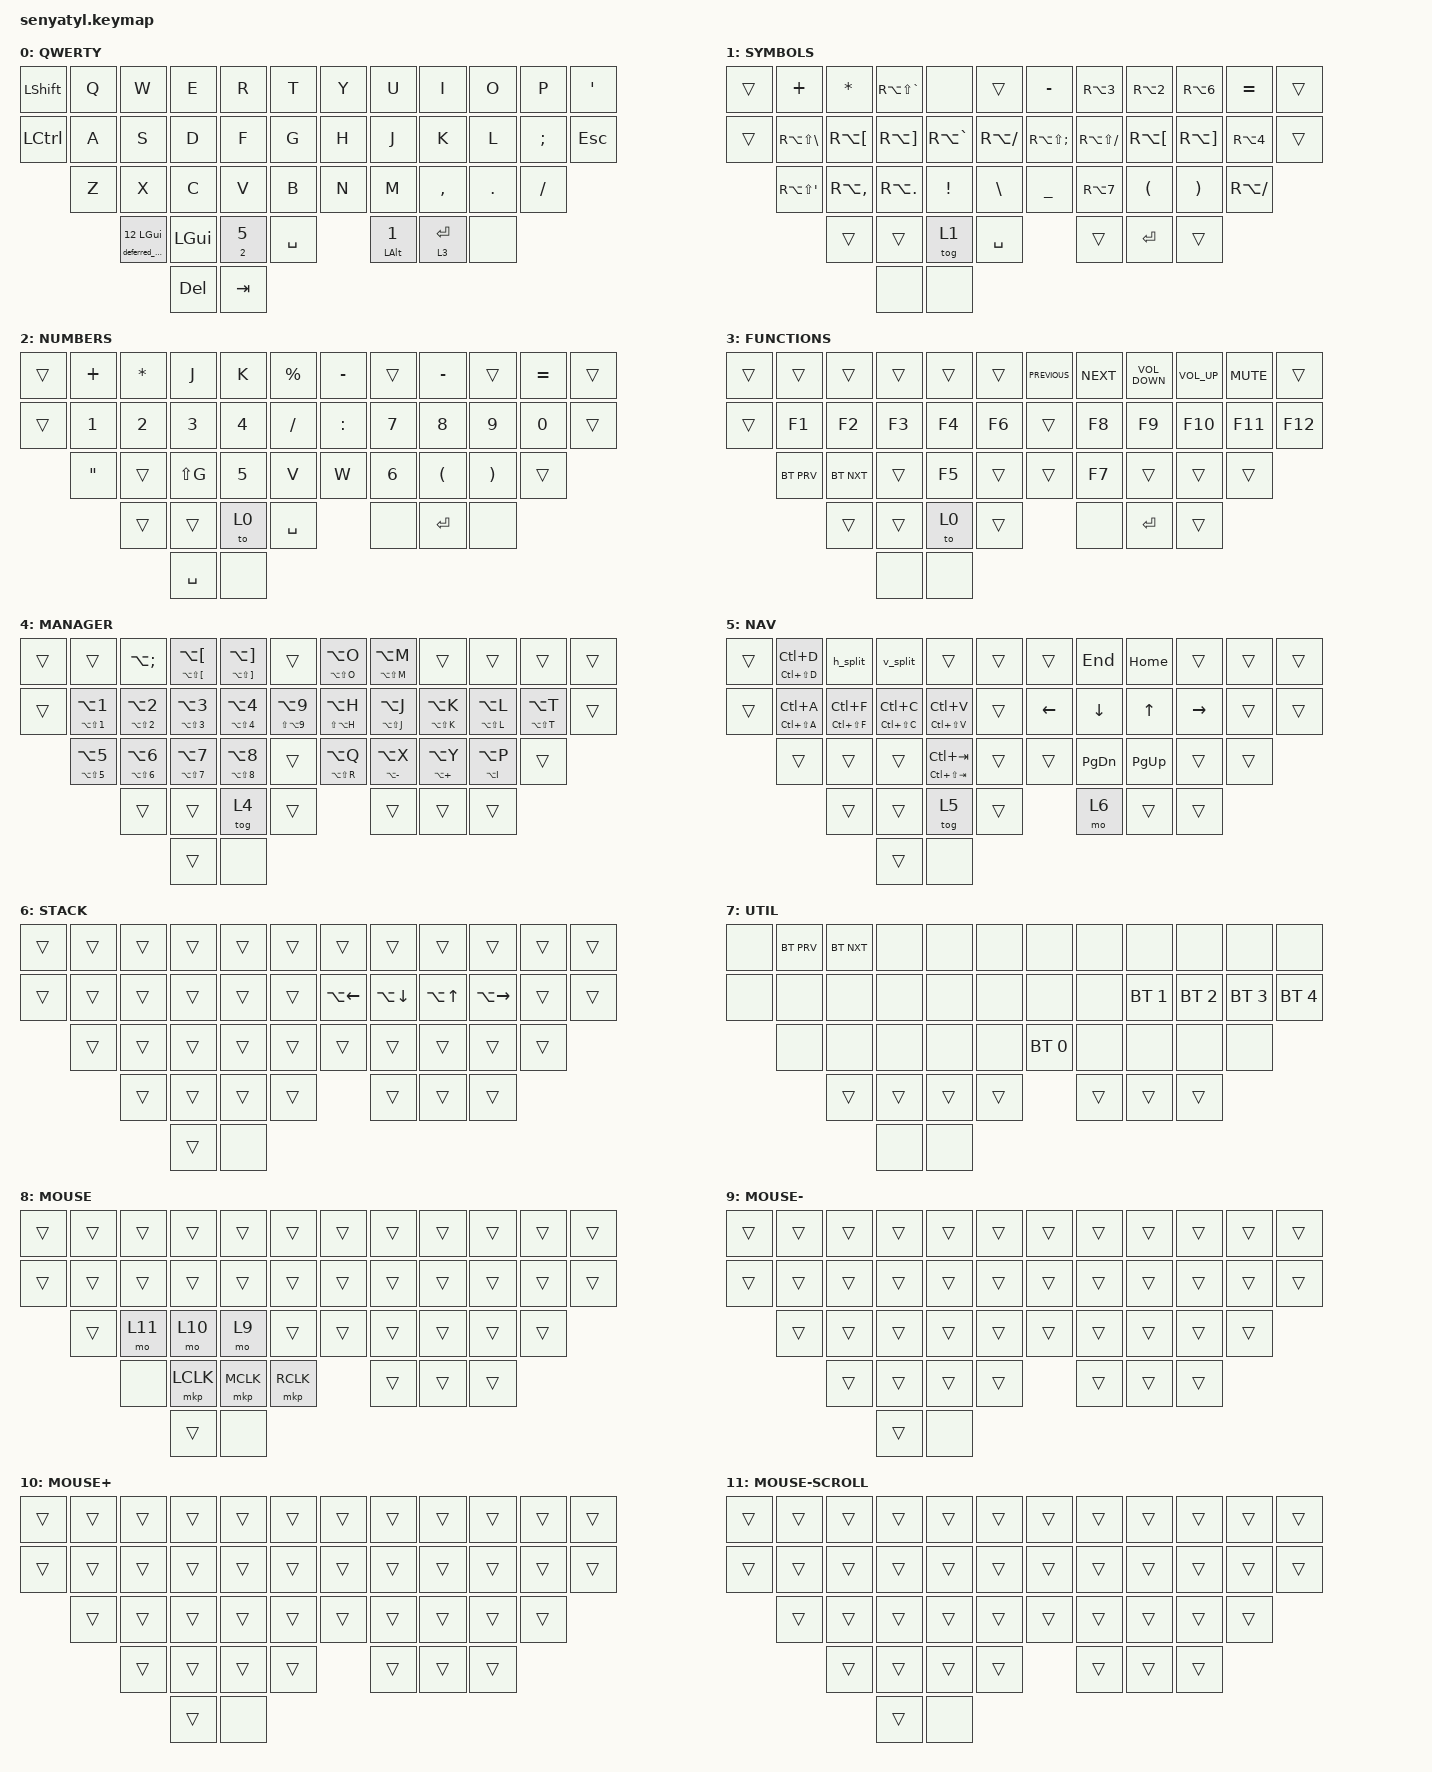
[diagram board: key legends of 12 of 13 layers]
#include <dt-bindings/zmk/mouse.h>
#include <input/processors.dtsi>
#include <zephyr/dt-bindings/input/input-event-codes.h>
#include <behaviors/deferred_mod.dtsi>
#include <behaviors/num_word.dtsi>
#include <behaviors.dtsi>
#include <dt-bindings/zmk/bt.h>
#include <dt-bindings/zmk/keys.h>
#include <dt-bindings/zmk/pointing.h>

/ {
    tapping-term-ms = <200>;
    flavor = "balanced";
    quick-tap-ms = <150>;
};

&mmv_input_listener { input-processors = <&zip_xy_scaler 2 1>; };

&msc_input_listener { input-processors = <&zip_scroll_scaler 2 1>; };

&msc {
    acceleration-exponent = <1>;
    time-to-max-speed-ms = <100>;
    delay-ms = <0>;
};

&mmv {
    time-to-max-speed-ms = <500>;
    acceleration-exponent = <1>;
    trigger-period-ms = <16>;
};

&soft_off { hold-time-ms = <2000>; };

/ {
    behaviors {
        smart_num_nav: smart_num_nav {
            compatible = "zmk,behavior-hold-tap";
            #binding-cells = <2>;
            flavor = "hold-preferred";
            tapping-term-ms = <200>;
            quick-tap-ms = <175>;
            require-prior-idle-ms = <125>;
            bindings = <&num_word_backspace>, <&nav_word>;

            display-name = "Smart Num/Nav";
        };

        nav_word: nav_word {
            compatible = "zmk,behavior-auto-layer";
            #binding-cells = <1>;
            continue-list = <LEFT DOWN UP RIGHT PG_DN PG_UP HOME END>;
            ignore-modifiers;
        };

        num_word_backspace: num_word_backspace {
            compatible = "zmk,behavior-auto-layer";
            #binding-cells = <1>;
            continue-list = <
                N1 N2 N3 N4 N5 N6 N7 N8 N9 N0
                NUMBER_1 NUMBER_2 NUMBER_3 NUMBER_4 NUMBER_5
                NUMBER_6 NUMBER_7 NUMBER_8 NUMBER_9 NUMBER_0
                PLUS MINUS ASTERISK SLASH PRCNT EQUAL COLON
                LPAR RPAR LEFT_PARENTHESIS RIGHT_PARENTHESIS
                DQT BACKSPACE BSPC
            >;

            ignore-modifiers;
        };

        sym_word: sym_word {
            compatible = "zmk,behavior-auto-layer";
            #binding-cells = <1>;
            continue-list = <
                EXCL AT HASH DLLR PRCNT CARET AMPS ASTRK LPAR RPAR
                PLUS MINUS EQUAL UNDER
                LESS_THAN GREATER_THAN SEMICOLON COLON SLASH QMARK SQT DQT
                LEFT_BRACKET RIGHT_BRACKET LEFT_BRACE RIGHT_BRACE
                BACKSLASH PIPE GRAVE TILDE BACKSPACE BSPC
                N1 N2 N3 N4 N5 N6 N7 N8 N9 N0
                LBKT RBKT BSLH SEMI COMMA PERIOD FSLH
            >;

            ignore-modifiers;
        };

        win_word: win_word {
            compatible = "zmk,behavior-auto-layer";
            #binding-cells = <1>;
            continue-list = <
                SEMICOLON LEFT_BRACKET RIGHT_BRACKET
                O M
                N1 N2 N3 N4 N5 N6 N7 N8 N9
                H J K L T
                Q P I
                X Y
                MINUS PLUS BACKSPACE BSPC
            >;

            ignore-modifiers;
        };

        del_behavior: del_behavior {
            compatible = "zmk,behavior-mod-morph";
            label = "DEL_BEHAVIOR";
            bindings = <&kp BACKSPACE>, <&kp DELETE>;

            #binding-cells = <0>;
            mods = <(MOD_LALT)>;
        };

        dot_overwrite: dot_overwrite {
            compatible = "zmk,behavior-mod-morph";
            label = "DOT_OVERWRITE";
            bindings = <&kp PERIOD>, <&kp COMMA>;

            #binding-cells = <0>;
            mods = <(MOD_LSFT)>;
        };

        smart_sym_alt: smart_sym_alt {
            compatible = "zmk,behavior-hold-tap";
            #binding-cells = <2>;
            flavor = "hold-preferred";
            tapping-term-ms = <200>;
            quick-tap-ms = <175>;
            require-prior-idle-ms = <125>;
            bindings = <&kp &sym_word>;
            display-name = "Smart Sym/Alt";
        };
    };

    combos {
        compatible = "zmk,combos";

        softoff {
            bindings = <&soft_off>;
            key-positions = <1 14 25>;
        };

        caps_word_combo {
            bindings = <&caps_word>;
            key-positions = <36 38>;
            layers = <0>;
        };

        lpkt {
            bindings = <&kp LEFT_PARENTHESIS>;
            key-positions = <4 5>;
            layers = <0>;
        };

        lbrt {
            bindings = <&kp LEFT_BRACKET>;
            key-positions = <17 16>;
            layers = <0>;
        };

        lbrs {
            bindings = <&kp LEFT_BRACE>;
            key-positions = <28 27>;
            layers = <0>;
        };

        rpkt {
            bindings = <&kp RIGHT_PARENTHESIS>;
            key-positions = <6 7>;
            layers = <0>;
        };

        rbrt {
            bindings = <&kp RIGHT_BRACKET>;
            key-positions = <19 18>;
            layers = <0>;
        };

        rbrs {
            bindings = <&kp RIGHT_BRACE>;
            key-positions = <30 30 29>;
            layers = <0>;
        };

        qw_esc {
            bindings = <&kp ESC>;
            key-positions = <25 26>;
            layers = <0>;
        };

        to_util_left {
            bindings = <&tog 7>;
            key-positions = <0 5 36>;
            layers = <0>;
        };

        to_util_right {
            bindings = <&tog 7>;
            key-positions = <6 11 38>;
            layers = <0>;
        };

        from_util_left {
            bindings = <&tog 7>;
            key-positions = <0 5 36>;
            layers = <7>;
        };

        from_util_right {
            bindings = <&tog 7>;
            key-positions = <6 11 38>;
            layers = <7>;
        };

        shrug_combo {
            bindings = <&shrug>;
            key-positions = <2 3 4>;
            layers = <1>;
        };

        sys_reset_left {
            bindings = <&sys_reset>;
            key-positions = <0 12>;
            layers = <7>;
        };

        bootloader_left {
            bindings = <&bootloader>;
            key-positions = <12 24>;
            layers = <7>;
        };

        sys_reset_right {
            bindings = <&sys_reset>;
            key-positions = <11 23>;
            layers = <7>;
        };

        bootloader_right {
            bindings = <&bootloader>;
            key-positions = <23 33>;
            layers = <7>;
        };

        bt_clear {
            bindings = <&bt BT_CLR_ALL>;
            key-positions = <4 3 2>;
            layers = <7>;
        };

        bt_clear_curr {
            bindings = <&bt BT_CLR>;
            key-positions = <14 15 16>;
            layers = <7>;
        };

        new_q {
            bindings = <&kp Q>;
            key-positions = <2 3>;
            layers = <0>;
        };

        new_z {
            bindings = <&kp Z>;
            key-positions = <3 4>;
            layers = <0>;
        };

        gth {
            bindings = <&gth>;
            key-positions = <4 16>;
            layers = <0>;
        };

        lthc {
            bindings = <&lth>;
            key-positions = <16 27>;
            layers = <0>;
        };

        h_tagc {
            bindings = <&h_tag>;
            key-positions = <7 19>;
        };

        arrowc {
            bindings = <&arrow>;
            key-positions = <8 20>;
        };

        to_win {
            bindings = <&win_word 4>;
            key-positions = <15 20>;
        };

        bksp_new {
            bindings = <&kp BACKSPACE>;
            key-positions = <32 31>;
        };

        to0 {
            bindings = <&to 0>;
            key-positions = <42 41>;
        };
    };

    macros {
        shrug: shrug {
            compatible = "zmk,behavior-macro";
            #binding-cells = <0>;
            bindings = <&macro_tap>, <&kp SEMI &kp S &kp H &kp R &kp U &kp G>;
        };

        gth: gth {
            compatible = "zmk,behavior-macro";
            #binding-cells = <0>;
            bindings = <&kp GT &kp EQUAL>;
            label = "GTH";
        };

        lth: lth {
            compatible = "zmk,behavior-macro";
            #binding-cells = <0>;
            bindings = <&kp LT &kp EQUAL>;
            label = "LTH";
        };

        arrow: arrow {
            compatible = "zmk,behavior-macro";
            #binding-cells = <0>;
            bindings = <&kp EQUAL &kp GT>;
            label = "ARROW";
        };

        h_tag: h_tag {
            compatible = "zmk,behavior-macro";
            #binding-cells = <0>;
            bindings = <&kp POUND>;
            label = "H_TAG";
        };

        v_split: v_split {
            compatible = "zmk,behavior-macro";
            #binding-cells = <0>;
            bindings = <&macro_tap>, <&kp LC(B) &kp PRCNT>;

            label = "V_SPLIT";
        };

        h_split: h_split {
            compatible = "zmk,behavior-macro";
            #binding-cells = <0>;
            bindings = <&macro_tap>, <&kp LC(B) &kp DQT>;

            label = "H_SPLIT";
        };
    };

    keymap {
        compatible = "zmk,keymap";

        layer_0 {
            display-name = "QWERTY";
            bindings = <
&kp LEFT_SHIFT  &kp Q  &kp W                            &kp E         &kp R               &kp T             &kp Y  &kp U                      &kp I        &kp O       &kp P     &kp SQT
&kp LCTRL       &kp A  &kp S                            &kp D         &kp F               &kp G             &kp H  &kp J                      &kp K        &kp L       &kp SEMI  &kp ESC
                &kp Z  &kp X                            &kp C         &kp V               &kp B             &kp N  &kp M                      &kp COMMA    &kp PERIOD  &kp FSLH
                       &deferred_mod_layer 12 LEFT_GUI  &kp LEFT_GUI  &smart_num_nav 2 5         &kp SPACE         &smart_sym_alt LEFT_ALT 1  &lt 3 ENTER  &none
                                                        &kp DEL       &kp TAB
            >;
        };

        layer_1 {
            display-name = "SYMBOLS";
            bindings = <
&trans  &kp PLUS          &kp ASTRK      &kp RA(LS(GRAVE))  &none          &trans                   &kp MINUS         &kp RA(N3)        &kp RA(N2)    &kp RA(N6)    &kp EQUAL     &trans
&trans  &kp RA(LS(BSLH))  &kp RA(LBKT)   &kp RA(RBKT)       &kp RA(GRAVE)  &kp RA(FSLH)             &kp RA(LS(SEMI))  &kp RA(LS(FSLH))  &kp RA(LBKT)  &kp RA(RBKT)  &kp RA(N4)    &trans
        &kp RA(LS(SQT))   &kp RA(COMMA)  &kp RA(PERIOD)     &kp EXCL       &kp BSLH                 &kp UNDER         &kp RA(N7)        &kp LPAR      &kp RPAR      &kp RA(FSLH)
                          &trans         &trans             &tog 1                       &kp SPACE                    &trans            &kp ENTER     &trans
                                         &none              &none
            >;
        };

        layer_2 {
            display-name = "NUMBERS";
            bindings = <
&trans  &kp PLUS  &kp ASTERISK  &kp J      &kp K   &kp PRCNT             &kp MINUS  &trans  &kp MINUS  &trans    &kp EQUAL  &trans
&trans  &kp N1    &kp N2        &kp N3     &kp N4  &kp SLASH             &kp COLON  &kp N7  &kp N8     &kp N9    &kp N0     &trans
        &kp DQT   &trans        &kp LS(G)  &kp N5  &kp V                 &kp W      &kp N6  &kp LPAR   &kp RPAR  &trans
                  &trans        &trans     &to 0              &kp SPACE             &none   &kp ENTER  &none
                                &kp SPACE  &none
            >;
        };

        layer_3 {
            display-name = "FUNCTIONS";
            bindings = <
&trans  &trans      &trans      &trans  &trans  &trans          &kp C_PREVIOUS  &kp C_NEXT  &kp C_VOLUME_DOWN  &kp C_VOLUME_UP  &kp C_MUTE  &trans
&trans  &kp F1      &kp F2      &kp F3  &kp F4  &kp F6          &trans          &kp F8      &kp F9             &kp F10          &kp F11     &kp F12
        &bt BT_PRV  &bt BT_NXT  &trans  &kp F5  &trans          &trans          &kp F7      &trans             &trans           &trans
                    &trans      &trans  &to 0           &trans                  &none       &kp ENTER          &trans
                                &none   &none
            >;
        };

        layer_4 {
            display-name = "MANAGER";
            bindings = <
&trans  &trans                 &kp LA(SEMI)                       &mt LA(LS(LBKT)) LA(LBKT)  &mt LA(LS(RBKT)) LA(RBKT)  &trans                         &mt LA(LS(O)) LA(O)  &mt LA(LS(M)) LA(M)  &trans               &trans               &trans               &trans
&trans  &mt LA(LS(N1)) LA(N1)  &mt LA(LS(N2)) LA(N2)              &mt LA(LS(N3)) LA(N3)      &mt LA(LS(N4)) LA(N4)      &mt LS(LA(N9)) LA(N9)          &mt LS(LA(H)) LA(H)  &mt LA(LS(J)) LA(J)  &mt LA(LS(K)) LA(K)  &mt LA(LS(L)) LA(L)  &mt LA(LS(T)) LA(T)  &trans
        &mt LA(LS(N5)) LA(N5)  &mt LA(LS(NUMBER_6)) LA(NUMBER_6)  &mt LA(LS(N7)) LA(N7)      &mt LA(LS(N8)) LA(N8)      &trans                         &mt LA(LS(R)) LA(Q)  &mt LA(MINUS) LA(X)  &mt LA(PLUS) LA(Y)   &mt LA(I) LA(P)      &trans
                               &trans                             &trans                     &tog 4                                            &trans                       &trans               &trans               &trans
                                                                  &trans                     &none
            >;
        };

        layer_5 {
            display-name = "NAV";
            bindings = <
&trans  &mt LC(LS(D)) LC(D)  &h_split             &v_split             &trans                   &trans          &trans    &kp END    &kp HOME   &trans     &trans  &trans
&trans  &mt LC(LS(A)) LC(A)  &mt LC(LS(F)) LC(F)  &mt LC(LS(C)) LC(C)  &mt LC(LS(V)) LC(V)      &trans          &kp LEFT  &kp DOWN   &kp UP     &kp RIGHT  &trans  &trans
        &trans               &trans               &trans               &mt LC(LS(TAB)) LC(TAB)  &trans          &trans    &kp PG_DN  &kp PG_UP  &trans     &trans
                             &trans               &trans               &tog 5                           &trans            &mo 6      &trans     &trans
                                                  &trans               &none
            >;
        };

        layer_6 {
            display-name = "STACK";
            bindings = <
&trans  &trans  &trans  &trans  &trans  &trans          &trans        &trans        &trans      &trans         &trans  &trans
&trans  &trans  &trans  &trans  &trans  &trans          &kp LA(LEFT)  &kp LA(DOWN)  &kp LA(UP)  &kp LA(RIGHT)  &trans  &trans
        &trans  &trans  &trans  &trans  &trans          &trans        &trans        &trans      &trans         &trans
                &trans  &trans  &trans          &trans                &trans        &trans      &trans
                        &trans  &none
            >;
        };

        layer_7 {
            display-name = "UTIL";
            bindings = <
&none  &bt BT_PRV  &bt BT_NXT  &none   &none   &none          &none         &none   &none         &none         &none         &none
&none  &none       &none       &none   &none   &none          &none         &none   &bt BT_SEL 1  &bt BT_SEL 2  &bt BT_SEL 3  &bt BT_SEL 4
       &none       &none       &none   &none   &none          &bt BT_SEL 0  &none   &none         &none         &none
                   &trans      &trans  &trans         &trans                &trans  &trans        &trans
                               &none   &none
            >;
        };

        layer_8 {
            display-name = "MOUSE";
            bindings = <
&trans  &trans  &trans  &trans     &trans     &trans             &trans  &trans  &trans  &trans  &trans  &trans
&trans  &trans  &trans  &trans     &trans     &trans             &trans  &trans  &trans  &trans  &trans  &trans
        &trans  &mo 11  &mo 10     &mo 9      &trans             &trans  &trans  &trans  &trans  &trans
                &none   &mkp LCLK  &mkp MCLK          &mkp RCLK          &trans  &trans  &trans
                        &trans     &none
            >;
        };

        layer_9 {
            display-name = "MOUSE-";
            bindings = <
&trans  &trans  &trans  &trans  &trans  &trans          &trans  &trans  &trans  &trans  &trans  &trans
&trans  &trans  &trans  &trans  &trans  &trans          &trans  &trans  &trans  &trans  &trans  &trans
        &trans  &trans  &trans  &trans  &trans          &trans  &trans  &trans  &trans  &trans
                &trans  &trans  &trans          &trans          &trans  &trans  &trans
                        &trans  &none
            >;
        };

        layer_10 {
            display-name = "MOUSE+";
            bindings = <
&trans  &trans  &trans  &trans  &trans  &trans          &trans  &trans  &trans  &trans  &trans  &trans
&trans  &trans  &trans  &trans  &trans  &trans          &trans  &trans  &trans  &trans  &trans  &trans
        &trans  &trans  &trans  &trans  &trans          &trans  &trans  &trans  &trans  &trans
                &trans  &trans  &trans          &trans          &trans  &trans  &trans
                        &trans  &none
            >;
        };

        layer_11 {
            display-name = "MOUSE-SCROLL";
            bindings = <
&trans  &trans  &trans  &trans  &trans  &trans          &trans  &trans  &trans  &trans  &trans  &trans
&trans  &trans  &trans  &trans  &trans  &trans          &trans  &trans  &trans  &trans  &trans  &trans
        &trans  &trans  &trans  &trans  &trans          &trans  &trans  &trans  &trans  &trans
                &trans  &trans  &trans          &trans          &trans  &trans  &trans
                        &trans  &none
            >;
        };

        layer_12 {
            display-name = "WINSPACE";
            bindings = <
&trans  &trans  &trans  &trans  &trans  &trans                           &trans  &trans  &trans  &trans  &trans  &trans
&trans  &trans  &trans  &trans  &trans  &trans                           &trans  &trans  &trans  &trans  &trans  &trans
        &trans  &trans  &trans  &trans  &trans                           &trans  &trans  &trans  &trans  &trans
                &trans  &trans  &trans          &deferred_mod_tap SPACE          &trans  &trans  &trans
                        &trans  &none
            >;
        };
    };
};
